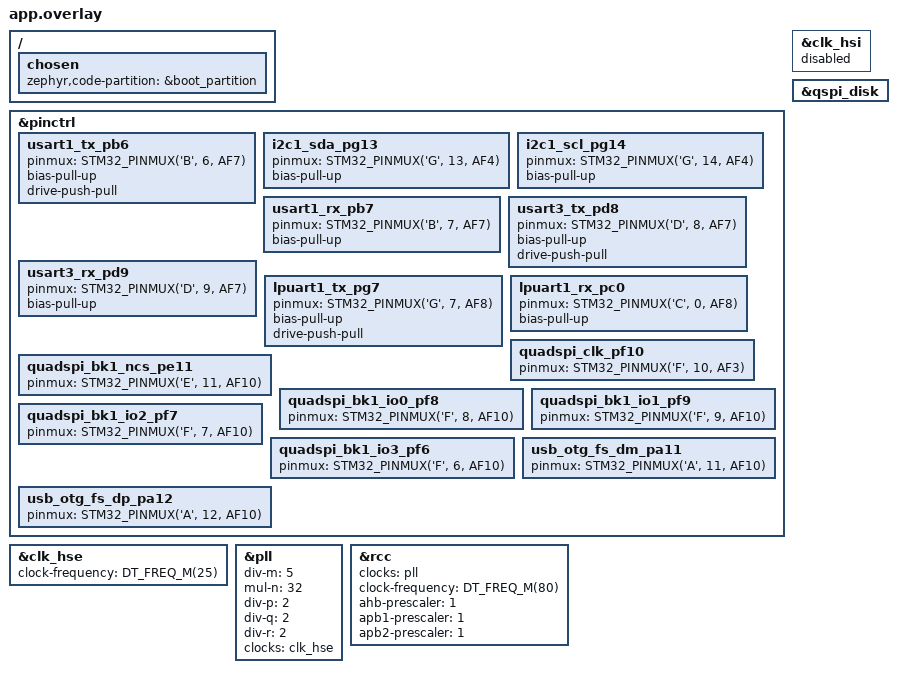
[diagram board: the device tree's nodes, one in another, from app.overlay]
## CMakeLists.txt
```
# SPDX-License-Identifier: Apache-2.0
cmake_minimum_required(VERSION 3.28.0)

set(BOARD_ROOT ${CMAKE_CURRENT_LIST_DIR}/../..)
find_package(Zephyr REQUIRED HINTS $ENV{ZEPHYR_BASE})
project(ef800_bootloader)

target_sources(app PRIVATE
	src/main.c
	src/boot_handoff.c
	src/boot_update.c
	src/boot_watchdog_early.c
	src/boot_watchdog_reset.c
	${CMAKE_CURRENT_LIST_DIR}/../../shared/ef800_boot/ef800_boot_decision.c
	${CMAKE_CURRENT_LIST_DIR}/../../shared/ef800_update/ef800_update.c
	${CMAKE_CURRENT_LIST_DIR}/../../shared/ef800_update/ef800_firmware_package.c
	${CMAKE_CURRENT_LIST_DIR}/../../shared/ef800_update/ef800_metadata.c
	${CMAKE_CURRENT_LIST_DIR}/../../shared/ef800_ports/ef800_console.c
	${CMAKE_CURRENT_LIST_DIR}/../../shared/ef800_ports/ef800_log_backend.c
	${CMAKE_CURRENT_LIST_DIR}/../../shared/ef800_watchdog/ef800_watchdog.c
	${CMAKE_CURRENT_LIST_DIR}/../../shared/ef800_storage/ef800_qspi_layout.c
)


target_include_directories(app PRIVATE
	${CMAKE_CURRENT_LIST_DIR}/../../shared/ef800_update
	${CMAKE_CURRENT_LIST_DIR}/../../shared/ef800_ports
	${CMAKE_CURRENT_LIST_DIR}/../../shared/ef800_measurement
	${CMAKE_CURRENT_LIST_DIR}/../../shared/ef800_boot
	${CMAKE_CURRENT_LIST_DIR}/../../shared/ef800_watchdog
	${CMAKE_CURRENT_LIST_DIR}/../../shared/ef800_storage
)
```

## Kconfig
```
# SPDX-License-Identifier: Apache-2.0

menu "EF800 bootloader"

config EF800_BOOT_MAIN_FAILURE_LIMIT
	int "EF800 application watchdog failure limit"
	default 3
	range 1 255
	help
	  Select the backup application after this many watchdog resets while
	  the EF800 application was the selected target.

endmenu

source "Kconfig.zephyr"
```

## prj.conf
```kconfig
# SPDX-License-Identifier: Apache-2.0
CONFIG_IS_BOOTLOADER=y
CONFIG_FLASH=y
CONFIG_FLASH_MAP=y
CONFIG_FLASH_PAGE_LAYOUT=y
CONFIG_DISK_DRIVERS=y
CONFIG_DISK_DRIVER_FLASH=y
CONFIG_FILE_SYSTEM=y
CONFIG_FAT_FILESYSTEM_ELM=y
# EF800_APP.pkg is a 13-character FAT long filename; keep the working buffer
# bounded because this bootloader nearly fills its 64 KiB flash partition.
CONFIG_FS_FATFS_LFN=y
CONFIG_FS_FATFS_LFN_MODE_STACK=y
CONFIG_FS_FATFS_MAX_LFN=13
CONFIG_NVS=y
CONFIG_NVS_DATA_CRC=y
CONFIG_HWINFO=y
CONFIG_WATCHDOG=y
CONFIG_IWDG_STM32_INITIAL_TIMEOUT=10000
CONFIG_REBOOT=y
CONFIG_LOG=y
CONFIG_LOG_BACKEND_UART=n
CONFIG_LOG_MODE_IMMEDIATE=y
CONFIG_BOOT_BANNER=y
CONFIG_SERIAL=y
CONFIG_UART_INTERRUPT_DRIVEN=y
CONFIG_UART_USE_RUNTIME_CONFIGURE=y
CONFIG_MAIN_STACK_SIZE=4096

# Keep the QSPI/FAT path disabled until the fitted NOR device is confirmed.
CONFIG_EF800_BOOT_MAIN_FAILURE_LIMIT=3

# The second-level bootloader occupies the first fixed partition selected by
# app.overlay.
CONFIG_USE_DT_CODE_PARTITION=y
```

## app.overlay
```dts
/* SPDX-License-Identifier: Apache-2.0 */

/ {
	chosen {
		zephyr,code-partition = &boot_partition;
	};
};

#include <zephyr/dt-bindings/pinctrl/stm32-pinctrl.h>

&pinctrl {
	usart1_tx_pb6: usart1_tx_pb6 {
		pinmux = <STM32_PINMUX('B', 6, AF7)>;
		bias-pull-up;
		drive-push-pull;
	};

	i2c1_sda_pg13: i2c1_sda_pg13 {
		pinmux = <STM32_PINMUX('G', 13, AF4)>;
		bias-pull-up;
	};

	i2c1_scl_pg14: i2c1_scl_pg14 {
		pinmux = <STM32_PINMUX('G', 14, AF4)>;
		bias-pull-up;
	};

	usart1_rx_pb7: usart1_rx_pb7 {
		pinmux = <STM32_PINMUX('B', 7, AF7)>;
		bias-pull-up;
	};

	usart3_tx_pd8: usart3_tx_pd8 {
		pinmux = <STM32_PINMUX('D', 8, AF7)>;
		bias-pull-up;
		drive-push-pull;
	};

	usart3_rx_pd9: usart3_rx_pd9 {
		pinmux = <STM32_PINMUX('D', 9, AF7)>;
		bias-pull-up;
	};

	lpuart1_tx_pg7: lpuart1_tx_pg7 {
		pinmux = <STM32_PINMUX('G', 7, AF8)>;
		bias-pull-up;
		drive-push-pull;
	};

	lpuart1_rx_pc0: lpuart1_rx_pc0 {
		pinmux = <STM32_PINMUX('C', 0, AF8)>;
		bias-pull-up;
	};

	quadspi_clk_pf10: quadspi_clk_pf10 {
		pinmux = <STM32_PINMUX('F', 10, AF3)>;
	};

	quadspi_bk1_ncs_pe11: quadspi_bk1_ncs_pe11 {
		pinmux = <STM32_PINMUX('E', 11, AF10)>;
	};

	quadspi_bk1_io0_pf8: quadspi_bk1_io0_pf8 {
		pinmux = <STM32_PINMUX('F', 8, AF10)>;
	};

	quadspi_bk1_io1_pf9: quadspi_bk1_io1_pf9 {
		pinmux = <STM32_PINMUX('F', 9, AF10)>;
	};

	quadspi_bk1_io2_pf7: quadspi_bk1_io2_pf7 {
		pinmux = <STM32_PINMUX('F', 7, AF10)>;
	};

	quadspi_bk1_io3_pf6: quadspi_bk1_io3_pf6 {
		pinmux = <STM32_PINMUX('F', 6, AF10)>;
	};

	usb_otg_fs_dm_pa11: usb_otg_fs_dm_pa11 {
		pinmux = <STM32_PINMUX('A', 11, AF10)>;
	};

	usb_otg_fs_dp_pa12: usb_otg_fs_dp_pa12 {
		pinmux = <STM32_PINMUX('A', 12, AF10)>;
	};
};

&clk_hse {
	clock-frequency = <DT_FREQ_M(25)>;
	status = "okay";
};

&clk_hsi {
	status = "disabled";
};

&pll {
	div-m = <5>;
	mul-n = <32>;
	div-p = <2>;
	div-q = <2>;
	div-r = <2>;
	clocks = <&clk_hse>;
	status = "okay";
};

&rcc {
	clocks = <&pll>;
	clock-frequency = <DT_FREQ_M(80)>;
	ahb-prescaler = <1>;
	apb1-prescaler = <1>;
	apb2-prescaler = <1>;
};

/* Keep the update disk available to an explicitly enabled storage build. */
&qspi_disk {
	status = "okay";
};
```

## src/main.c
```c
/* SPDX-License-Identifier: Apache-2.0 */
/** @file @brief Select, validate, and hand off to EF800 firmware images. */

#include <stdbool.h>
#include <stddef.h>
#include <stdint.h>
#include <string.h>
#include <inttypes.h>
#include <errno.h>

#include <zephyr/device.h>
#include <zephyr/devicetree.h>
#include <zephyr/kernel.h>
#include <zephyr/logging/log.h>
#include <zephyr/storage/flash_map.h>
#include <zephyr/sys/printk.h>
#include <zephyr/sys/util.h>

#if CONFIG_HWINFO
#include <zephyr/drivers/hwinfo.h>
#endif

#include "ef800_update.h"
#include "ef800_metadata.h"
#include "ef800_console.h"
#include "boot_update.h"
#include "ef800_boot_decision.h"
#include "ef800_watchdog.h"
#include "boot_trace.h"
#include "boot_handoff.h"

LOG_MODULE_REGISTER(ef800_bootloader, LOG_LEVEL_WRN);

#define MAIN_PARTITION_ID PARTITION_ID(main_partition)
#define BACKUP_PARTITION_ID PARTITION_ID(backup_partition)
#define QSPI_BOOTSTATE_PARTITION_ID PARTITION_ID(qspi_bootstate_partition)
#define QSPI_CONFIGURATION_PARTITION_ID PARTITION_ID(qspi_configuration_partition)
#define QSPI_DATA_PARTITION_ID PARTITION_ID(qspi_storage_partition)
#define QSPI_ERASE_BLOCK_SIZE 0x00001000U

BUILD_ASSERT(PARTITION_EXISTS(main_partition), "main partition is required");
BUILD_ASSERT(PARTITION_EXISTS(backup_partition), "backup partition is required");
BUILD_ASSERT(PARTITION_EXISTS(metadata_partition), "external boot metadata NVS is required");
BUILD_ASSERT(PARTITION_EXISTS(qspi_bootstate_partition), "QSPI boot-state partition is required");
BUILD_ASSERT(PARTITION_EXISTS(qspi_configuration_partition), "QSPI configuration partition is required");
BUILD_ASSERT(PARTITION_EXISTS(qspi_storage_partition), "QSPI shared-data partition is required");
BUILD_ASSERT(PARTITION_OFFSET(boot_partition) == 0x00000000U,
	     "bootloader partition offset must remain 0x00000000");
BUILD_ASSERT(PARTITION_SIZE(boot_partition) == 0x00010000U,
	     "bootloader partition size must remain 64 KiB");
BUILD_ASSERT(PARTITION_OFFSET(backup_partition) == 0x00010000U,
	     "backup partition offset must remain 0x00010000");
BUILD_ASSERT(PARTITION_SIZE(backup_partition) == 0x00020000U,
	     "backup partition size must remain 128 KiB");
BUILD_ASSERT(PARTITION_OFFSET(main_partition) ==
	     PARTITION_OFFSET(backup_partition) + PARTITION_SIZE(backup_partition),
	     "EF800 Application must follow the expanded EF800 Backup region");
BUILD_ASSERT(PARTITION_OFFSET(qspi_bootstate_partition) == 0x00000000U &&
	     PARTITION_SIZE(qspi_bootstate_partition) == 0x00008000U,
	     "QSPI boot-state partition must be the first 32 KiB");
BUILD_ASSERT(PARTITION_OFFSET(metadata_partition) == 0x00000000U &&
	     PARTITION_SIZE(metadata_partition) == 0x00008000U,
	     "metadata NVS must alias the QSPI boot-state partition");
BUILD_ASSERT(PARTITION_OFFSET(qspi_configuration_partition) == 0x00008000U &&
	     PARTITION_SIZE(qspi_configuration_partition) == 0x000F8000U,
	     "QSPI configuration partition must be 992 KiB after boot-state NVS");
BUILD_ASSERT(PARTITION_OFFSET(qspi_storage_partition) == 0x00100000U &&
	     PARTITION_SIZE(qspi_storage_partition) == 0x00300000U,
	     "QSPI shared-data partition must be the final 3 MiB");
BUILD_ASSERT((PARTITION_OFFSET(qspi_bootstate_partition) % QSPI_ERASE_BLOCK_SIZE) == 0U &&
	     (PARTITION_SIZE(qspi_bootstate_partition) % QSPI_ERASE_BLOCK_SIZE) == 0U &&
	     (PARTITION_OFFSET(qspi_configuration_partition) % QSPI_ERASE_BLOCK_SIZE) == 0U &&
	     (PARTITION_SIZE(qspi_configuration_partition) % QSPI_ERASE_BLOCK_SIZE) == 0U &&
	     (PARTITION_OFFSET(qspi_storage_partition) % QSPI_ERASE_BLOCK_SIZE) == 0U &&
	     (PARTITION_SIZE(qspi_storage_partition) % QSPI_ERASE_BLOCK_SIZE) == 0U,
	     "all QSPI partitions must align to the 4 KiB erase granularity");
BUILD_ASSERT(PARTITION_OFFSET(main_partition) == 0x00030000U,
	     "main partition offset must remain 0x00030000");
BUILD_ASSERT(PARTITION_SIZE(main_partition) == 0x000D0000U,
	     "main partition size must remain 832 KiB");

static const uintptr_t sram_address = DT_REG_ADDR(DT_NODELABEL(sram0));
static const size_t sram_size = DT_REG_SIZE(DT_NODELABEL(sram0));

static int read_vector(const struct flash_area *area, uint32_t vector[2])
{
	if (!flash_area_device_is_ready(area) || area->fa_size < 2U * sizeof(uint32_t)) {
		return -ENODEV;
	}

	return flash_area_read(area, 0U, vector, 2U * sizeof(uint32_t));
}

static bool partition_is_valid(const struct flash_area *area, uintptr_t address)
{
	uint32_t vector[2];

	if (read_vector(area, vector) != 0) {
		return false;
	}

	return ef800_vector_table_valid(vector, address, area->fa_size,
					 sram_address, sram_size);
}

static bool reset_was_watchdog(void)
{
#if CONFIG_HWINFO
	uint32_t cause;
	bool watchdog = false;

	if (hwinfo_get_reset_cause(&cause) == 0) {
		watchdog = (cause & RESET_WATCHDOG) != 0U;
		/* Prevent accumulated reset flags from counting the same failure twice. */
		(void)hwinfo_clear_reset_cause();
	}
	return watchdog;
#else
	return false;
#endif
}

int main(void)
{
	int watchdog_result;
	int console_result;
	const struct flash_area *main_area;
	const struct flash_area *backup_area;
	struct ef800_boot_metadata metadata __aligned(8);
	bool metadata_valid = false;
	bool metadata_dirty = false;
	bool watchdog_reset = false;
	bool main_valid;
	bool backup_valid;
	bool use_backup = false;
	bool update_installed = false;
	int rc;

	/* Start/feed the option-byte IWDG before slow flash and metadata work. */
	watchdog_result = ef800_watchdog_start(10000U);
	console_result = ef800_console_init(true);
	ef800_boot_trace("bootloader: entered main\r\n");
	ef800_boot_trace_result("console init", console_result);
	printk("ef800 bootloader: main (console=%u, init=%d)\r\n",
		ef800_console_get_target(), console_result);
	if (watchdog_result != 0) {
		LOG_WRN("IWDG could not be initialized at boot");
	}

	rc = flash_area_open(MAIN_PARTITION_ID, &main_area);
	if (rc < 0 || !flash_area_device_is_ready(main_area)) {
		LOG_ERR("main partition unavailable: %d", rc);
		return 0;
	}
	rc = flash_area_open(BACKUP_PARTITION_ID, &backup_area);
	if (rc < 0 || !flash_area_device_is_ready(backup_area)) {
		LOG_ERR("backup partition unavailable: %d", rc);
		return 0;
	}

	rc = ef800_metadata_read_current(&metadata, &metadata_valid);
	if (rc < 0 || !metadata_valid) {
		LOG_WRN("boot-state NVS unavailable; using volatile defaults "
			"(failure counter unavailable): %d", rc);
		ef800_boot_metadata_init(&metadata);
		metadata_valid = false;
		metadata_dirty = true;
	}

	if (metadata_valid) {
		watchdog_reset = reset_was_watchdog();
		if (metadata.last_target == EF800_BOOT_TARGET_BACKUP) {
			/* Backup is a recovery boot, not a permanent boot target. */
			metadata.main_failures = 0U;
			metadata.last_target = EF800_BOOT_TARGET_MAIN;
			metadata_dirty = true;
			LOG_INF("backup recovery boot complete; retrying EF800 application");
		} else if (watchdog_reset &&
			metadata.last_target == EF800_BOOT_TARGET_MAIN &&
			metadata.main_failures < UINT32_MAX) {
			metadata.main_failures++;
			metadata_dirty = true;
			LOG_WRN("main watchdog failure %u/%u", metadata.main_failures,
				CONFIG_EF800_BOOT_MAIN_FAILURE_LIMIT);
		}
	}

	LOG_INF("checking MTP EF800 Application update");
	rc = ef800_boot_install_update(main_area, PARTITION_ADDRESS(main_partition),
					 sram_address, sram_size);
	update_installed = rc == 0;
	LOG_INF("MTP EF800 Application update result: %d", rc);
	ef800_boot_trace_result("EF800 Application update", rc);
	if (rc < 0 && rc != -ENOENT && rc != -ENODEV) {
		LOG_WRN("update inspection failed: %d", rc);
	}
	if (update_installed) {
		metadata.main_failures = 0U;
		metadata.last_target = EF800_BOOT_TARGET_MAIN;
		metadata_dirty = true;
	}

	main_valid = partition_is_valid(main_area, PARTITION_ADDRESS(main_partition));
	backup_valid = partition_is_valid(backup_area,
					 PARTITION_ADDRESS(backup_partition));

	use_backup = ef800_boot_decide(&(struct ef800_boot_decision_input){
		.main_valid = main_valid,
		.backup_valid = backup_valid,
		.failure_limit_reached = metadata.last_target == EF800_BOOT_TARGET_MAIN &&
			metadata.main_failures >=
			CONFIG_EF800_BOOT_MAIN_FAILURE_LIMIT,
	}) == EF800_BOOT_DECISION_BACKUP;

	if (use_backup && backup_valid) {
		LOG_WRN("main failure limit reached; starting backup");
		metadata.last_target = EF800_BOOT_TARGET_BACKUP;
		metadata_dirty = true;
		if (metadata_dirty) {
			rc = ef800_metadata_write_current(&metadata);
			if (rc < 0) {
				LOG_ERR("boot metadata write failed: %d", rc);
			}
		}
		ef800_boot_handoff(backup_area, PARTITION_ADDRESS(backup_partition),
				   sram_address, sram_size);
	}

	if (main_valid) {
		/* A non-watchdog reset is the only safe indication that main ran. */
		if (!watchdog_reset && metadata.main_failures != 0U) {
			metadata.main_failures = 0U;
			metadata_dirty = true;
		}
		if (metadata.last_target != EF800_BOOT_TARGET_MAIN) {
			metadata.last_target = EF800_BOOT_TARGET_MAIN;
			metadata_dirty = true;
		}
		if (metadata_dirty) {
			rc = ef800_metadata_write_current(&metadata);
			if (rc < 0) {
				LOG_ERR("boot metadata write failed: %d", rc);
			}
		}
		LOG_INF("starting EF800 application");
		ef800_boot_handoff(main_area, PARTITION_ADDRESS(main_partition),
				   sram_address, sram_size);
	}

	if (backup_valid) {
		if (metadata.last_target != EF800_BOOT_TARGET_BACKUP) {
			metadata.last_target = EF800_BOOT_TARGET_BACKUP;
			metadata_dirty = true;
		}
		if (metadata_dirty) {
			rc = ef800_metadata_write_current(&metadata);
			if (rc < 0) {
				LOG_ERR("boot metadata write failed: %d", rc);
			}
		}
		LOG_WRN("EF800 application invalid; starting backup");
		ef800_boot_handoff(backup_area, PARTITION_ADDRESS(backup_partition),
				   sram_address, sram_size);
	}

	LOG_ERR("no valid main or backup application");
	while (true) {
		k_sleep(K_FOREVER);
	}
}
```

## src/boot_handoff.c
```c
/* SPDX-License-Identifier: Apache-2.0 */

#include "boot_handoff.h"

#include <stdbool.h>
#include <errno.h>
#include <stdint.h>

#include <cmsis_core.h>
#include <zephyr/kernel.h>
#include <zephyr/logging/log.h>
#include <zephyr/sys/util.h>

#include "ef800_update.h"

LOG_MODULE_REGISTER(ef800_boot_handoff, LOG_LEVEL_INF);

#define EF800_VECTOR_BYTES (2U * sizeof(uint32_t))

static int read_vector(const struct flash_area *area, uint32_t vector[2])
{
	if (!flash_area_device_is_ready(area) || area->fa_size < EF800_VECTOR_BYTES) {
		return -ENODEV;
	}

	return flash_area_read(area, 0U, vector, EF800_VECTOR_BYTES);
}

__attribute__((naked, noreturn)) static void branch_to_application(
	uint32_t stack_pointer, uint32_t reset_handler)
{
	__asm__ volatile (
		"msr msp, r0\n"
		"movs r0, #0\n"
		"msr control, r0\n"
		"msr basepri, r0\n"
		"msr faultmask, r0\n"
		"isb\n"
		"cpsie i\n"
		"bx r1\n"
	);
}

FUNC_NORETURN void ef800_boot_handoff(const struct flash_area *area,
				      uintptr_t address,
				      uintptr_t sram_address,
				      size_t sram_size)
{
	uint32_t vector[2];

	if (read_vector(area, vector) != 0 ||
		!ef800_vector_table_valid(vector, address, area->fa_size,
					  sram_address, sram_size)) {
		LOG_ERR("refusing handoff to invalid image at 0x%lx",
			(unsigned long)address);
		while (true) {
			k_sleep(K_FOREVER);
		}
	}
	__disable_irq();
	SysTick->CTRL = 0U;
	SysTick->LOAD = 0U;
	SysTick->VAL = 0U;
	SCB->ICSR = SCB_ICSR_PENDSTCLR_Msk | SCB_ICSR_PENDSVCLR_Msk;
	for (size_t index = 0U; index < ARRAY_SIZE(NVIC->ICER); ++index) {
		NVIC->ICER[index] = UINT32_MAX;
		NVIC->ICPR[index] = UINT32_MAX;
	}
	MPU->CTRL = 0U;
	SCB->CFSR = SCB->CFSR;
	SCB->HFSR = SCB->HFSR;
	SCB->VTOR = (uint32_t)address;
	__DSB();
	__ISB();
	branch_to_application(vector[0], vector[1]);
}
```

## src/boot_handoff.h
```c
/* SPDX-License-Identifier: Apache-2.0 */
/** @file
 * @brief Validate and transfer control from the bootloader to a firmware image.
 */

#ifndef EF800_BOOT_HANDOFF_H
#define EF800_BOOT_HANDOFF_H

#include <stddef.h>
#include <stdint.h>

#include <zephyr/storage/flash_map.h>
#include <zephyr/sys/util.h>

/** @brief Configure the image's memory state and branch to its reset vector.
 * @param area Flash area containing the image.
 * @param address Image base address.
 * @param sram_address SRAM bounds used to validate the initial stack pointer.
 * @param sram_size Size of the valid SRAM region.
 * @return Does not return; invalid images are rejected or trigger a fatal path.
 */
FUNC_NORETURN void ef800_boot_handoff(const struct flash_area *area,
				      uintptr_t address,
				      uintptr_t sram_address,
				      size_t sram_size);

#endif /* EF800_BOOT_HANDOFF_H */
```

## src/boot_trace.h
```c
/* SPDX-License-Identifier: Apache-2.0 */
/** @file @brief Emit early boot diagnostics over the bootloader UART. */
#ifndef EF800_BOOT_TRACE_H
#define EF800_BOOT_TRACE_H

#include <zephyr/kernel.h>

#if !defined(CONFIG_BOARD_NATIVE_SIM)
#include <zephyr/device.h>
#include <zephyr/devicetree.h>
#include <zephyr/drivers/uart.h>

/** @brief Write diagnostic text to UART4; a no-op on native_sim.
 * @param text NUL-terminated message.
 * @return None.
 */
static inline void ef800_boot_trace(const char *text)
{
	const struct device *uart = DEVICE_DT_GET(DT_NODELABEL(uart4));

	if (text == NULL || !device_is_ready(uart)) {
		return;
	}
	while (*text != '\0') {
		uart_poll_out(uart, (uint8_t)*text++);
	}
}

/** @brief Format and emit a boot-update stage result.
 * @param stage Short stage name.
 * @param result Stage result/status code.
 * @return None.
 */
static inline void ef800_boot_trace_result(const char *stage, int result)
{
	char line[96];

	snprintk(line, sizeof(line), "boot update: %s rc=%d\r\n", stage, result);
	ef800_boot_trace(line);
}
#else

/** @brief Native-simulation no-op implementation of boot tracing.
 * @param text Ignored diagnostic text.
 * @return None.
 */
static inline void ef800_boot_trace(const char *text)
{
	ARG_UNUSED(text);
}

/** @brief Native-simulation no-op implementation of result tracing.
 * @param stage Ignored stage name.
 * @param result Ignored result code.
 * @return None.
 */
static inline void ef800_boot_trace_result(const char *stage, int result)
{
	ARG_UNUSED(stage);
	ARG_UNUSED(result);
}
#endif

#endif /* EF800_BOOT_TRACE_H */
```

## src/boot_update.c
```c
/* SPDX-License-Identifier: Apache-2.0 */

#include "boot_update.h"

#include <errno.h>
#include <string.h>

#include <ff.h>
#include <zephyr/drivers/flash.h>
#include <zephyr/fs/fs.h>
#include <zephyr/logging/log.h>
#include <zephyr/storage/flash_map.h>
#include <zephyr/sys/util.h>

#include "ef800_update.h"
#include "ef800_firmware_package.h"
#include "ef800_qspi_layout.h"
#include "ef800_watchdog.h"
#include "boot_trace.h"

LOG_MODULE_REGISTER(ef800_boot_update, LOG_LEVEL_WRN);

#define EF800_PACKAGE_PATH "/DATA:/fwu/EF800_APP.pkg"
#define EF800_BOOTSTRAP_PATH "/DATA:/fwu/EF800_FW.bin"
#define EF800_UPDATE_CHUNK 1024U
#define EF800_VECTOR_BYTES (2U * sizeof(uint32_t))

static int file_read_exact(struct fs_file_t *file, void *buffer, size_t length)
{
	size_t offset = 0U;

	while (offset < length) {
		ssize_t count = fs_read(file, (uint8_t *)buffer + offset,
					length - offset);

		if (count < 0) {
			return (int)count;
		}
		if (count == 0) {
			return -EIO;
		}
		offset += (size_t)count;
	}
	return 0;
}

static int verify_update_crc(struct fs_file_t *file, off_t source_offset,
			     size_t image_size, uint32_t expected_crc)
{
	uint8_t buffer[EF800_UPDATE_CHUNK];
	size_t remaining = image_size;
	uint32_t crc = 0U;
	int rc;

	if (source_offset < 0 || fs_seek(file, source_offset, FS_SEEK_SET) < 0) {
		return -EIO;
	}
	while (remaining != 0U) {
		size_t count = MIN(remaining, sizeof(buffer));

		rc = file_read_exact(file, buffer, count);
		if (rc != 0) {
			return rc;
		}
		crc = ef800_crc32_update(crc, buffer, count);
		(void)ef800_watchdog_feed();
		remaining -= count;
	}
	if (crc != expected_crc) {
		LOG_ERR("update CRC mismatch: expected=0x%08x actual=0x%08x",
			expected_crc, crc);
		return -EBADMSG;
	}
	return 0;
}

static int erase_partition_watchdog_safe(const struct flash_area *area)
{
	size_t offset = 0U;
	size_t page_count = 0U;

	ef800_boot_trace("boot update: erase begin\r\n");
	while (offset < area->fa_size) {
		struct flash_pages_info page = {0};
		off_t absolute_offset = area->fa_off + (off_t)offset;
		int rc = flash_get_page_info_by_offs(area->fa_dev, absolute_offset,
						     &page);

		if (rc != 0 || page.size == 0U ||
		    page.start_offset != (off_t)absolute_offset ||
		    page.size > area->fa_size - offset) {
			LOG_ERR("invalid erase page at offset=%u: %d size=%u",
				(unsigned int)offset, rc, (unsigned int)page.size);
			ef800_boot_trace("boot update: invalid erase page\r\n");
			return rc != 0 ? rc : -EINVAL;
		}
		rc = flash_area_erase(area, offset, page.size);
		if (rc < 0) {
			LOG_ERR("partition erase failed at offset=%u size=%u: %d",
				(unsigned int)offset, (unsigned int)page.size, rc);
			ef800_boot_trace("boot update: erase failed\r\n");
			return rc;
		}
		offset += page.size;
		page_count++;
		(void)ef800_watchdog_feed();
		if ((page_count % 32U) == 0U) {
			LOG_INF("main partition erase progress: %u/%u bytes",
				(unsigned int)offset, (unsigned int)area->fa_size);
		}
	}
	ef800_boot_trace("boot update: erase complete\r\n");
	return 0;
}

static bool partition_is_valid(const struct flash_area *area, uintptr_t address,
				       uintptr_t sram_address, size_t sram_size)
{
	uint32_t vector[2] = {0U, 0U};

	if (flash_area_read(area, 0U, vector, sizeof(vector)) != 0) {
		return false;
	}
	return ef800_vector_table_valid(vector, address, area->fa_size,
					sram_address, sram_size);
}

static int copy_update_image(struct fs_file_t *file, const struct flash_area *area,
				     off_t source_offset, size_t image_size,
				     bool has_crc, uint32_t expected_crc)
{
	uint8_t source[EF800_UPDATE_CHUNK] __aligned(8);
	uint8_t verify[EF800_UPDATE_CHUNK] __aligned(8);
	size_t remaining = image_size;
	size_t destination = 0U;
	size_t alignment = flash_area_align(area);
	uint32_t crc = 0U;
	int rc;

	if (alignment == 0U || alignment > sizeof(source)) {
		return -EINVAL;
	}
	LOG_INF("erasing main partition page-by-page: size=%u",
		(unsigned int)area->fa_size);
	rc = erase_partition_watchdog_safe(area);
	if (rc < 0) {
		LOG_ERR("main partition erase failed: %d", rc);
		ef800_boot_trace_result("partition erase", rc);
		return rc;
	}
	LOG_INF("main partition erase complete");
	while (remaining != 0U) {
		size_t count = MIN(remaining, sizeof(source));
		size_t write_count = ROUND_UP(count, alignment);

		if (write_count > sizeof(source) || destination > area->fa_size ||
			write_count > area->fa_size - destination || source_offset < 0) {
			return -EINVAL;
		}
		rc = fs_seek(file, source_offset, FS_SEEK_SET);
		if (rc < 0) {
			LOG_ERR("update seek failed at offset=%ld: %d",
				(long)source_offset, rc);
			ef800_boot_trace_result("source seek", rc);
			return rc;
		}
		rc = file_read_exact(file, source, count);
		if (rc < 0) {
			LOG_ERR("update read failed at offset=%ld count=%u: %d",
				(long)source_offset, (unsigned int)count, rc);
			ef800_boot_trace_result("source read", rc);
			return -EIO;
		}
		if (write_count > count) {
			memset(source + count, 0xff, write_count - count);
		}
		if (has_crc) {
			crc = ef800_crc32_update(crc, source, count);
		}
		rc = flash_area_write(area, destination, source, write_count);
		if (rc < 0) {
			LOG_ERR("main flash write failed at offset=%u count=%u: %d",
				(unsigned int)destination, (unsigned int)write_count, rc);
			ef800_boot_trace_result("main flash write", rc);
			return rc;
		}
		rc = flash_area_read(area, destination, verify, write_count);
		if (rc < 0 || memcmp(source, verify, write_count) != 0) {
			LOG_ERR("main flash readback failed at offset=%u count=%u: %d",
				(unsigned int)destination, (unsigned int)write_count, rc);
			ef800_boot_trace_result("main flash readback", rc < 0 ? rc : -EIO);
			return rc < 0 ? rc : -EIO;
		}
		source_offset += (off_t)count;
		destination += write_count;
		remaining -= count;
		(void)ef800_watchdog_feed();
	}
	ef800_boot_trace("boot update: program/readback complete\r\n");
	LOG_INF("main image programmed and read back: size=%u",
		(unsigned int)image_size);
	return !has_crc || crc == expected_crc ? 0 : -EBADMSG;
}

int ef800_boot_install_update(const struct flash_area *main_area,
				      uintptr_t main_address,
				      uintptr_t sram_address, size_t sram_size)
{
	static FATFS fat_fs;
	struct fs_mount_t mount = {
		.type = FS_FATFS,
		.mnt_point = "/DATA:",
		.fs_data = &fat_fs,
		.storage_dev = (void *)PARTITION_ID(qspi_storage_partition),
		.flags = FS_MOUNT_FLAG_NO_FORMAT,
	};
	struct fs_file_t file;
	struct fs_dirent entry;
	const struct flash_area *boot_state_area;
	struct ef800_update_header header;
	struct ef800_firmware_package_header package_header;
	struct ef800_firmware_semver coordinator_version = {
		.major = EF800_FIRMWARE_INITIAL_VERSION_MAJOR,
		.minor = EF800_FIRMWARE_INITIAL_VERSION_MINOR,
		.patch = EF800_FIRMWARE_INITIAL_VERSION_PATCH,
	};
	uint8_t package_wire_header[EF800_FIRMWARE_PACKAGE_HEADER_SIZE];
	uint32_t magic;
	uint32_t vector[2];
	uint32_t expected_crc = 0U;
	const char *update_path = EF800_PACKAGE_PATH;
	off_t source_offset = 0;
	size_t image_size;
	bool mounted = false;
	bool opened = false;
	bool has_crc = false;
	bool legacy_layout;
	int rc;

	fs_file_t_init(&file);
	LOG_INF("EF800 Application update scan: %s", EF800_PACKAGE_PATH);
	ef800_boot_trace("boot update: scan begin\r\n");
	rc = flash_area_open(PARTITION_ID(qspi_bootstate_partition),
		&boot_state_area);
	if (rc != 0) {
		LOG_ERR("boot-state partition open failed: %d", rc);
		ef800_boot_trace_result("state partition open", rc);
		return rc;
	}
	rc = ef800_qspi_layout_check_legacy_area(boot_state_area,
		&legacy_layout);
	flash_area_close(boot_state_area);
	if (rc != 0) {
		LOG_ERR("QSPI layout check failed: %d", rc);
		ef800_boot_trace_result("QSPI layout check", rc);
		return rc;
	}
	if (legacy_layout) {
		LOG_WRN("legacy monolithic QSPI FAT detected; EF800 Application update scan skipped");
		return -ENOTSUP;
	}
	rc = fs_mount(&mount);
	if (rc < 0) {
		LOG_ERR("update filesystem mount failed: %d", rc);
		ef800_boot_trace_result("filesystem mount", rc);
		return rc;
	}
	mounted = true;
	LOG_INF("update filesystem mounted");
	ef800_boot_trace("boot update: filesystem mounted\r\n");
	rc = fs_stat(update_path, &entry);
	if (rc < 0) {
		/*
		 * The raw legacy path is a recovery/bootstrap fallback only. Never
		 * let it overwrite a valid, package-aware EF800 Application.
		 */
		if (partition_is_valid(main_area, main_address, sram_address,
				       sram_size)) {
			rc = -ENOENT;
			goto out;
		}
		update_path = EF800_BOOTSTRAP_PATH;
		rc = fs_stat(update_path, &entry);
	}
	if (rc < 0 || entry.type != FS_DIR_ENTRY_FILE) {
		rc = rc < 0 ? rc : -ENOENT;
		LOG_WRN("update file unavailable: %d", rc);
		ef800_boot_trace_result("update file lookup", rc);
		goto out;
	}
	LOG_INF("update file found: size=%u", (unsigned int)entry.size);
	ef800_boot_trace("boot update: update file found\r\n");
	if (entry.size < EF800_VECTOR_BYTES) {
		rc = -EINVAL;
		LOG_ERR("update file is too small: %u", (unsigned int)entry.size);
		ef800_boot_trace_result("update file size", rc);
		goto out;
	}
	rc = fs_open(&file, update_path, FS_O_READ);
	if (rc < 0) {
		LOG_ERR("update file open failed: %d", rc);
		ef800_boot_trace_result("update file open", rc);
		goto out;
	}
	opened = true;
	if (fs_seek(&file, 0, FS_SEEK_SET) < 0 ||
		file_read_exact(&file, &magic, sizeof(magic)) < 0) {
		rc = -EIO;
		goto out;
	}
	if (strcmp(update_path, EF800_PACKAGE_PATH) == 0) {
		if (entry.size < sizeof(package_wire_header) ||
		    fs_seek(&file, 0, FS_SEEK_SET) < 0 ||
		    file_read_exact(&file, package_wire_header,
				    sizeof(package_wire_header)) < 0) {
			rc = -EINVAL;
			ef800_boot_trace_result("package header read", rc);
			goto out;
		}
		rc = ef800_firmware_package_header_parse(
			package_wire_header, sizeof(package_wire_header),
			(size_t)entry.size,
			EF800_FIRMWARE_TARGET_APPLICATION,
			EF800_FIRMWARE_HARDWARE_ID_L496,
			&coordinator_version, &package_header);
		if (rc != 0) {
			ef800_boot_trace_result("package header validation", rc);
			goto out;
		}
		image_size = package_header.image_size;
		source_offset = package_header.header_size;
		expected_crc = package_header.image_crc32;
		has_crc = true;
		LOG_INF("package image: size=%u base=0x%08x crc=0x%08x version=%u.%u.%u",
			(unsigned int)image_size, package_header.load_address,
			package_header.image_crc32, package_header.image_version.major,
			package_header.image_version.minor,
			package_header.image_version.patch);
	} else if (magic == EF800_UPDATE_MAGIC) {
		if (entry.size < sizeof(header) || fs_seek(&file, 0, FS_SEEK_SET) < 0 ||
			file_read_exact(&file, &header, sizeof(header)) < 0 ||
			!ef800_update_header_valid(&header, entry.size, main_address,
							    main_area->fa_size)) {
			rc = -EINVAL;
			ef800_boot_trace_result("update header validation", rc);
			goto out;
		}
		image_size = header.image_size;
		source_offset = header.header_size;
		expected_crc = header.image_crc32;
		has_crc = true;
		LOG_INF("header image: size=%u base=0x%08x crc=0x%08x",
			(unsigned int)image_size, header.load_address,
			header.image_crc32);
	} else {
		image_size = entry.size;
		LOG_INF("raw image: size=%u", (unsigned int)image_size);
	}
	if ((uintmax_t)source_offset > (uintmax_t)entry.size ||
		image_size > main_area->fa_size ||
		image_size > (size_t)entry.size - (size_t)source_offset ||
		fs_seek(&file, source_offset, FS_SEEK_SET) < 0 ||
		file_read_exact(&file, vector, sizeof(vector)) < 0 ||
		!ef800_vector_table_valid(vector, main_address, image_size,
					  sram_address, sram_size)) {
		rc = -EINVAL;
		LOG_ERR("image/vector validation failed: size=%u msp=0x%08x reset=0x%08x",
			(unsigned int)image_size, vector[0], vector[1]);
		ef800_boot_trace_result("image/vector validation", -EINVAL);
		goto out;
	}
	ef800_boot_trace("boot update: image/vector validated\r\n");
	if (has_crc) {
		rc = verify_update_crc(&file, source_offset, image_size,
				       expected_crc);
		if (rc < 0) {
			LOG_ERR("update CRC validation failed: %d", rc);
			ef800_boot_trace_result("CRC validation", rc);
			goto out;
		}
		LOG_INF("update CRC validated");
		ef800_boot_trace("boot update: CRC validated\r\n");
	}
	rc = copy_update_image(&file, main_area, source_offset, image_size, has_crc,
					       expected_crc);
	if (rc < 0 || !partition_is_valid(main_area, main_address, sram_address,
						  sram_size)) {
		rc = rc < 0 ? rc : -EBADMSG;
		LOG_ERR("installed image validation failed: %d", rc);
		ef800_boot_trace("boot update: installed image verification failed\r\n");
		goto out;
	}
	LOG_INF("installed EF800 Application image verified");
	ef800_boot_trace("boot update: image verified\r\n");
	rc = fs_close(&file);
	opened = false;
	if (rc == 0) {
		/* Deletion is best effort; the verified image is already installed. */
		int unlink_rc = fs_unlink(update_path);

		LOG_INF("update file cleanup: %d", unlink_rc);
		ef800_boot_trace("boot update: update file cleanup attempted\r\n");
	}
out:
	if (opened) {
		(void)fs_close(&file);
	}
	if (mounted) {
		int unmount_rc = fs_unmount(&mount);

		LOG_INF("update filesystem unmount: %d", unmount_rc);
		if (rc == 0) {
			rc = unmount_rc;
		}
	}
	LOG_INF("EF800 Application update scan complete: %d", rc);
	ef800_boot_trace_result("scan complete", rc);
	return rc;
}
```

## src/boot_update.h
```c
/* SPDX-License-Identifier: Apache-2.0 */
/** @file
 * @brief Install a validated main-firmware update using the SRAM staging area.
 */
#ifndef EF800_BOOT_UPDATE_H_
#define EF800_BOOT_UPDATE_H_

#include <stdbool.h>
#include <stddef.h>
#include <stdint.h>

struct flash_area;

/**
 * @brief Install a validated, staged EF800 Application image.
 *
 * @details Prefers `/DATA:/fwu/EF800_APP.pkg`, whose envelope, L496 target,
 * load address, minimum coordinator version, header/payload CRCs, vector
 * table, and partition bounds are validated before erase. When no package is
 * staged, the legacy `/DATA:/fwu/EF800_FW.bin` bootstrap path remains
 * available for the one-time transition; subsequent releases use the package
 * path. The payload is copied in bounded chunks; no full image-sized RAM
 * buffer is required. A staged file is removed only after flash readback and
 * installed-image validation succeed.
 *
 * @param main_area Open flash area for the EF800 Application partition.
 * @param main_address Authorized load address of that partition.
 * @param sram_address Start of valid SRAM used to validate the initial stack
 *        pointer in the candidate vector table.
 * @param sram_size Size in bytes of the valid SRAM range beginning at
 *        @p sram_address.
 * @return 0 after installation and verification; -ENOENT if neither update
 *         file exists; -EINVAL/-EBADMSG for invalid image data; or a negative
 *         errno for filesystem, validation, or flash-operation failures.
 */
int ef800_boot_install_update(const struct flash_area *main_area,
				      uintptr_t main_address,
				      uintptr_t sram_address, size_t sram_size);

#endif /* EF800_BOOT_UPDATE_H_ */
```

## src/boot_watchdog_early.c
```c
/* SPDX-License-Identifier: Apache-2.0 */

#include <zephyr/device.h>
#include <zephyr/devicetree.h>
#include <zephyr/init.h>

#include <stm32_ll_iwdg.h>

static int ef800_bootloader_watchdog_early_feed(void)
{
#if DT_HAS_ALIAS(watchdog0) && DT_NODE_HAS_STATUS(DT_ALIAS(watchdog0), okay)
	/* Option bytes may start IWDG before Zephyr reaches the application. */
	LL_IWDG_ReloadCounter(IWDG);
#endif
	return 0;
}

SYS_INIT(ef800_bootloader_watchdog_early_feed, PRE_KERNEL_1, 0);
```

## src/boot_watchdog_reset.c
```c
/* SPDX-License-Identifier: Apache-2.0 */

/* This hook runs before Zephyr initializes MSP/RAM or device drivers. */
__attribute__((naked, used)) void soc_early_reset_hook(void)
{
	__asm__ volatile (
		"ldr r0, =0x40003000\n"
		"movw r1, #0xaaaa\n"
		"str r1, [r0, #0]\n"
		"bx lr\n"
	);
}
```
